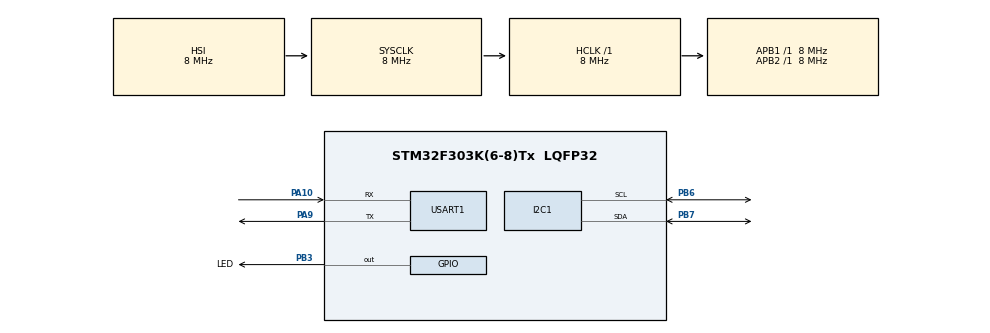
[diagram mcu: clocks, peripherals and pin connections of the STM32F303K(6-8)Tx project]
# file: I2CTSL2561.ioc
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Mcu.Family=STM32F3
Mcu.Name=STM32F303K(6-8)Tx
Mcu.Package=LQFP32
NVIC.PriorityGroup=NVIC_PRIORITYGROUP_4
PA10.Mode=Asynchronous
PA10.Signal=USART1_RX
PA13.Mode=Serial_Wire
PA13.Signal=SYS_JTMS-SWDIO
PA14.Mode=Serial_Wire
PA14.Signal=SYS_JTCK-SWCLK
PA9.Mode=Asynchronous
PA9.Signal=USART1_TX
PB3.GPIO_Label=LED
PB3.Signal=GPIO_Output
PB6.Mode=I2C
PB6.Signal=I2C1_SCL
PB7.Mode=I2C
PB7.Signal=I2C1_SDA
ProjectManager.HeapSize=0x200
ProjectManager.StackSize=0x400
ProjectManager.TargetToolchain=MDK-ARM V5.32
RCC.AHBFreq_Value=8000000
RCC.APB1Freq_Value=8000000
RCC.APB2Freq_Value=8000000
RCC.CortexFreq_Value=8000000
RCC.HSE_VALUE=8000000
RCC.HSI_VALUE=8000000
RCC.SYSCLKFreq_VALUE=8000000
USART1.VirtualMode-Asynchronous=VM_ASYNC
board=custom

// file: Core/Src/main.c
/* USER CODE BEGIN Header */
/**
  ******************************************************************************
  * @file           : main.c
  * @brief          : Main program body
  ******************************************************************************
  * @attention
  *
  * Copyright (c) 2022 STMicroelectronics.
  * All rights reserved.
  *
  * This software is licensed under terms that can be found in the LICENSE file
  * in the root directory of this software component.
  * If no LICENSE file comes with this software, it is provided AS-IS.
  *
  ******************************************************************************
  */
/* USER CODE END Header */
#include "main.h"
#include "i2c.h"
#include "usart.h"
#include "gpio.h"

#include <stdio.h>
#include <stdlib.h>
#include <string.h>
#include "tsl2561.h"
#include "Adafruit_TCS34725.h"
#include "ssd1306_tests.h"
#include "ssd1306.h"

void SystemClock_Config(void);

uint8_t debugStatus=0;
uint8_t state=1;
//Adafruit_TCS34725 tcs = Adafruit_TCS34725(TCS34725_INTEGRATIONTIME_700MS, TCS34725_GAIN_1X);
/* USER CODE END PV */

void SystemClock_Config(void);
/* USER CODE BEGIN PFP */

int main(void)
{

  /* MCU Configuration--------------------------------------------------------*/

  /* Reset of all peripherals, Initializes the Flash interface and the Systick. */
  HAL_Init();

  /* Configure the system clock */
  SystemClock_Config();

  /* Initialize all configured peripherals */
  MX_GPIO_Init();
  MX_I2C1_Init();
  MX_USART1_UART_Init();
	ssd1306_Init();
  /* USER CODE BEGIN 2 */

//  begin();
  // Set persistence filter to generate an interrupt for every RGB Cycle, regardless of the integration limits
//  write8(TCS34725_PERS, TCS34725_PERS_NONE);
//
	char buffer[256];
  sprintf(buffer, "Start2");
  HAL_UART_Transmit(&huart1, (uint8_t*)buffer, strlen(buffer), HAL_MAX_DELAY);
  HAL_Delay(1000);
	setInterrupt(true);

//  traceWrite(txt,20);
  /* USER CODE END 2 */

  /* Infinite loop */
  /* USER CODE BEGIN WHILE */
//	uint16_t lux;
	uint16_t broadband, ir;

	int clock = SystemCoreClock;
	char txt[200]={0};
	sprintf(txt,"clock= %d\n",clock);
	HAL_UART_Transmit(&huart1, (uint8_t*)txt, strlen(txt), HAL_MAX_DELAY);
	char rgbinf[50],colorTempinf[50],Luxinf[50],BLEinf[200];
  while (1)
  {
		//TCS34725
		tcs3272_init();
		uint16_t r, g, b,c, colorTemp, lux;
		HAL_GPIO_TogglePin(LED_GPIO_Port, LED_Pin);
    getRawData(&r, &g, &b, &c);
		getRGB(&r, &g, &b);
		colorTemp = calculateColorTemperature(r, g, b);
//    colorTemp = calculateColorTemperature_dn40(r, g, b,c);
//		lux = calculateLux(r, g, b);

		sprintf(rgbinf,"%d %d %d\n",r,g,b);
		sprintf(colorTempinf,"ColTe=%d",colorTemp);

//		HAL_UART_Transmit(&huart1, (uint8_t*)rgbinf, strlen(rgbinf), HAL_MAX_DELAY);
//		HAL_UART_Transmit(&huart1, (uint8_t*)colorTempinf, strlen(colorTempinf), HAL_MAX_DELAY);
		//TSL2561
		TSL2561_SetTiming(&hi2c1, TSL2561_INTEGRATIONTIME_101MS, TSL2561_GAIN_0X);
		// Check luminosity level and calculate lux
		TSL2561_GetLuminosity(&hi2c1, &broadband, &ir);
		lux = TSL2561_CalculateLux(broadband, ir);
//			int sz=sprintf(buffer, "broadband %u IR %u LUX %lu\r\n", broadband, ir, lux);
		sprintf(Luxinf,"LUX=%d",lux);
		sprintf(BLEinf,"R%dG%dB%dC%dL%d",r,g,b,colorTemp,lux);
		HAL_UART_Transmit(&huart1, (uint8_t*)BLEinf, strlen(BLEinf), HAL_MAX_DELAY);

		//SSD1306
//		ssd1306_TestAll();
//		ssd1306_lux(txt);
		ssd1306_showmessage(rgbinf,colorTempinf,Luxinf);

		HAL_Delay(500);
	}
  /* USER CODE END 3 */
}
void SystemClock_Config(void)
{
  RCC_OscInitTypeDef RCC_OscInitStruct = {0};
  RCC_ClkInitTypeDef RCC_ClkInitStruct = {0};
  RCC_PeriphCLKInitTypeDef PeriphClkInit = {0};

  /** Initializes the RCC Oscillators according to the specified parameters
  * in the RCC_OscInitTypeDef structure.
  */
  RCC_OscInitStruct.OscillatorType = RCC_OSCILLATORTYPE_HSI;
  RCC_OscInitStruct.HSIState = RCC_HSI_ON;
  RCC_OscInitStruct.HSICalibrationValue = RCC_HSICALIBRATION_DEFAULT;
  RCC_OscInitStruct.PLL.PLLState = RCC_PLL_NONE;
  if (HAL_RCC_OscConfig(&RCC_OscInitStruct) != HAL_OK)
  {
    Error_Handler();
  }
  /** Initializes the CPU, AHB and APB buses clocks
  */
  RCC_ClkInitStruct.ClockType = RCC_CLOCKTYPE_HCLK|RCC_CLOCKTYPE_SYSCLK
                              |RCC_CLOCKTYPE_PCLK1|RCC_CLOCKTYPE_PCLK2;
  RCC_ClkInitStruct.SYSCLKSource = RCC_SYSCLKSOURCE_HSI;
  RCC_ClkInitStruct.AHBCLKDivider = RCC_SYSCLK_DIV1;
  RCC_ClkInitStruct.APB1CLKDivider = RCC_HCLK_DIV1;
  RCC_ClkInitStruct.APB2CLKDivider = RCC_HCLK_DIV1;

  if (HAL_RCC_ClockConfig(&RCC_ClkInitStruct, FLASH_LATENCY_0) != HAL_OK)
  {
    Error_Handler();
  }
  PeriphClkInit.PeriphClockSelection = RCC_PERIPHCLK_USART1|RCC_PERIPHCLK_I2C1;
  PeriphClkInit.Usart1ClockSelection = RCC_USART1CLKSOURCE_PCLK1;
  PeriphClkInit.I2c1ClockSelection = RCC_I2C1CLKSOURCE_HSI;
  if (HAL_RCCEx_PeriphCLKConfig(&PeriphClkInit) != HAL_OK)
  {
    Error_Handler();
  }
}

void Error_Handler(void)
{
  __disable_irq();
  while (1)
  {
  }
}
